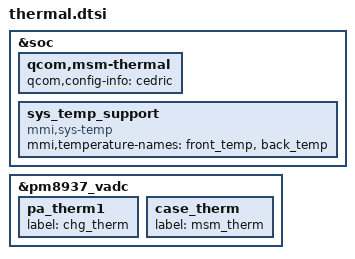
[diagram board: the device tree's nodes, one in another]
&soc {
	qcom,msm-thermal {
		qcom,config-info = "cedric";
	};

	sys_temp_support {
		compatible = "mmi,sys-temp";
		mmi,temperature-names = "front_temp",
					"back_temp";
		status = "ok";
	};
};

&pm8937_vadc {
	pa_therm1 {
		label = "chg_therm";
	};

	case_therm {
		label = "msm_therm";
	};
};
